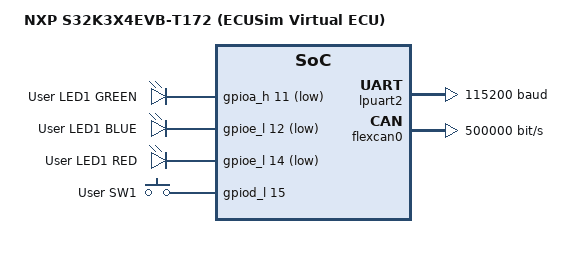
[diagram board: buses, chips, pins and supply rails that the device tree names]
/*
 * Copyright 2023-2024 NXP
 * Copyright 2024 TrueFidelity (ECUSim Virtual ECU adaptation)
 *
 * SPDX-License-Identifier: Apache-2.0
 */

/dts-v1/;
#include <arm/nxp/nxp_s32k344_m7.dtsi>
#include <dt-bindings/gpio/gpio.h>
#include <zephyr/dt-bindings/input/input-event-codes.h>
#include "s32k3x4evb-pinctrl.dtsi"

/ {
	model = "NXP S32K3X4EVB-T172 (ECUSim Virtual ECU)";
	compatible = "nxp,s32k3x4evb";

	chosen {
		zephyr,sram = &sram0_1;
		zephyr,flash = &flash0;
		zephyr,itcm = &itcm;
		zephyr,dtcm = &dtcm;
		zephyr,code-partition = &code_partition;
		zephyr,console = &lpuart2;
		zephyr,shell-uart = &lpuart2;
		zephyr,canbus = &flexcan0;
		zephyr,can-primary = &flexcan0;
	};

	aliases {
		led0 = &user_led1_red;
		led1 = &user_led1_green;
		led2 = &user_led1_blue;
		sw0 = &user_button_1;
	};

	leds {
		compatible = "gpio-leds";
		user_led1_green: user_led1_green {
			gpios = <&gpioa_h 11 GPIO_ACTIVE_LOW>;
			label = "User LED1 GREEN";
		};
		user_led1_blue: user_led1_blue {
			gpios = <&gpioe_l 12 GPIO_ACTIVE_LOW>;
			label = "User LED1 BLUE";
		};
		user_led1_red: user_led1_red {
			gpios = <&gpioe_l 14 GPIO_ACTIVE_LOW>;
			label = "User LED1 RED";
		};
	};

	gpio_keys {
		compatible = "gpio-keys";
		user_button_1: button_0 {
			label = "User SW1";
			gpios = <&gpiod_l 15 GPIO_ACTIVE_HIGH>;
			zephyr,code = <INPUT_KEY_0>;
		};
	};
};

&flash0 {
	partitions {
		compatible = "fixed-partitions";
		#address-cells = <1>;
		#size-cells = <1>;

		/* ECUSim expects IVT header at offset 0 from flash base */
		ivt_header: partition@0 {
			label = "ivt-header";
			reg = <0x00000000 0x100>;
		};

		code_partition: partition@100 {
			label = "code-partition";
			reg = <0x00000100 (DT_SIZE_K(4048) - 0x100)>;
		};
	};
};

/* GPIO ports needed for LEDs and buttons */
&gpioa_h {
	status = "okay";
};

&gpioe_l {
	status = "okay";
};

&gpioe_h {
	status = "okay";
};

&gpiod_l {
	status = "okay";
};

&gpiod_h {
	status = "okay";
};

/* UART for console */
&lpuart2 {
	pinctrl-0 = <&lpuart2_default>;
	pinctrl-names = "default";
	current-speed = <115200>;
	status = "okay";
};

/* CAN for ECU communication */
&flexcan0 {
	pinctrl-0 = <&flexcan0_default>;
	pinctrl-names = "default";
	bus-speed = <500000>;
	bus-speed-data = <5000000>;
	sample-point = <875>;
	sample-point-data = <875>;
	status = "okay";
};

/* DMA */
&edma0 {
	status = "okay";
};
